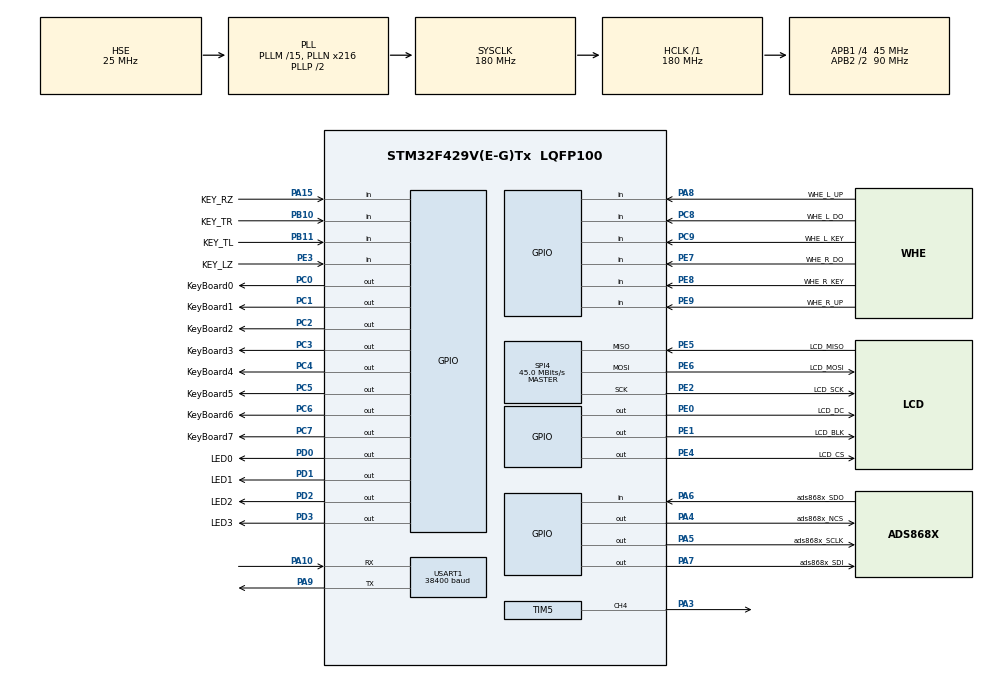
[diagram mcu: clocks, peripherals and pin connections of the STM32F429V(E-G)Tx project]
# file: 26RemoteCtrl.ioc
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DMA2D.ColorMode=DMA2D_OUTPUT_RGB565
Dma.Request0=USART1_TX
Dma.Request1=USART1_RX
Dma.Request2=SPI4_TX
Dma.SPI4_TX.2.Direction=DMA_MEMORY_TO_PERIPH
Dma.SPI4_TX.2.FIFOMode=DMA_FIFOMODE_DISABLE
Dma.SPI4_TX.2.Instance=DMA2_Stream1
Dma.SPI4_TX.2.MemDataAlignment=DMA_MDATAALIGN_HALFWORD
Dma.SPI4_TX.2.MemInc=DMA_MINC_ENABLE
Dma.SPI4_TX.2.Mode=DMA_NORMAL
Dma.SPI4_TX.2.PeriphDataAlignment=DMA_PDATAALIGN_HALFWORD
Dma.SPI4_TX.2.PeriphInc=DMA_PINC_DISABLE
Dma.SPI4_TX.2.Priority=DMA_PRIORITY_LOW
Dma.USART1_RX.1.Direction=DMA_PERIPH_TO_MEMORY
Dma.USART1_RX.1.FIFOMode=DMA_FIFOMODE_DISABLE
Dma.USART1_RX.1.Instance=DMA2_Stream2
Dma.USART1_RX.1.MemDataAlignment=DMA_MDATAALIGN_BYTE
Dma.USART1_RX.1.MemInc=DMA_MINC_ENABLE
Dma.USART1_RX.1.Mode=DMA_NORMAL
Dma.USART1_RX.1.PeriphDataAlignment=DMA_PDATAALIGN_BYTE
Dma.USART1_RX.1.PeriphInc=DMA_PINC_DISABLE
Dma.USART1_RX.1.Priority=DMA_PRIORITY_LOW
Dma.USART1_TX.0.Direction=DMA_MEMORY_TO_PERIPH
Dma.USART1_TX.0.FIFOMode=DMA_FIFOMODE_DISABLE
Dma.USART1_TX.0.Instance=DMA2_Stream7
Dma.USART1_TX.0.MemDataAlignment=DMA_MDATAALIGN_BYTE
Dma.USART1_TX.0.MemInc=DMA_MINC_ENABLE
Dma.USART1_TX.0.Mode=DMA_NORMAL
Dma.USART1_TX.0.PeriphDataAlignment=DMA_PDATAALIGN_BYTE
Dma.USART1_TX.0.PeriphInc=DMA_PINC_DISABLE
Dma.USART1_TX.0.Priority=DMA_PRIORITY_LOW
IWDG.Prescaler=IWDG_PRESCALER_64
IWDG.Reload=500
Mcu.Family=STM32F4
Mcu.Name=STM32F429V(E-G)Tx
Mcu.Package=LQFP100
NVIC.DMA2D_IRQn=true\:5\:0\:true\:false\:true\:true\:true\:true
NVIC.DMA2_Stream1_IRQn=true\:5\:0\:true\:false\:true\:false\:true\:true
NVIC.DMA2_Stream2_IRQn=true\:5\:0\:true\:false\:true\:false\:true\:true
NVIC.DMA2_Stream7_IRQn=true\:5\:0\:true\:false\:true\:false\:true\:true
NVIC.PriorityGroup=NVIC_PRIORITYGROUP_4
NVIC.TIM2_IRQn=true\:5\:0\:true\:false\:true\:true\:true\:true
NVIC.USART1_IRQn=true\:5\:0\:true\:false\:true\:true\:true\:true
PA10.GPIO_PuPd=GPIO_PULLUP
PA10.Mode=Asynchronous
PA10.Signal=USART1_RX
PA13.Mode=Trace_Asynchronous_SW
PA13.Signal=SYS_JTMS-SWDIO
PA14.Mode=Trace_Asynchronous_SW
PA14.Signal=SYS_JTCK-SWCLK
PA15.GPIO_Label=KEY_RZ
PA15.GPIO_PuPd=GPIO_PULLUP
PA15.Signal=GPIO_Input
PA3.Signal=S_TIM5_CH4
PA4.GPIO_Label=ads868x_NCS
PA4.GPIO_Speed=GPIO_SPEED_FREQ_VERY_HIGH
PA4.Signal=GPIO_Output
PA5.GPIO_Label=ads868x_SCLK
PA5.GPIO_Speed=GPIO_SPEED_FREQ_VERY_HIGH
PA5.Signal=GPIO_Output
PA6.GPIO_Label=ads868x_SDO
PA6.Signal=GPIO_Input
PA7.GPIO_Label=ads868x_SDI
PA7.GPIO_Speed=GPIO_SPEED_FREQ_VERY_HIGH
PA7.Signal=GPIO_Output
PA8.GPIO_Label=WHE_L_UP
PA8.GPIO_PuPd=GPIO_PULLDOWN
PA8.Signal=GPIO_Input
PA9.GPIO_PuPd=GPIO_PULLUP
PA9.Mode=Asynchronous
PA9.Signal=USART1_TX
PB10.GPIO_Label=KEY_TR
PB10.GPIO_PuPd=GPIO_PULLUP
PB10.Signal=GPIO_Input
PB11.GPIO_Label=KEY_TL
PB11.GPIO_PuPd=GPIO_PULLUP
PB11.Signal=GPIO_Input
PB3.Mode=Trace_Asynchronous_SW
PB3.Signal=SYS_JTDO-SWO
PC0.GPIO_Label=KeyBoard0
PC0.GPIO_ModeDefaultOutputPP=GPIO_MODE_OUTPUT_OD
PC0.GPIO_PuPd=GPIO_PULLUP
PC0.GPIO_Speed=GPIO_SPEED_FREQ_HIGH
PC0.Signal=GPIO_Output
PC1.GPIO_Label=KeyBoard1
PC1.GPIO_ModeDefaultOutputPP=GPIO_MODE_OUTPUT_OD
PC1.GPIO_PuPd=GPIO_PULLUP
PC1.GPIO_Speed=GPIO_SPEED_FREQ_HIGH
PC1.Signal=GPIO_Output
PC14/OSC32_IN.Mode=LSE-External-Oscillator
PC14/OSC32_IN.Signal=RCC_OSC32_IN
PC15/OSC32_OUT.Mode=LSE-External-Oscillator
PC15/OSC32_OUT.Signal=RCC_OSC32_OUT
PC2.GPIO_Label=KeyBoard2
PC2.GPIO_ModeDefaultOutputPP=GPIO_MODE_OUTPUT_OD
PC2.GPIO_PuPd=GPIO_PULLUP
PC2.GPIO_Speed=GPIO_SPEED_FREQ_HIGH
PC2.Signal=GPIO_Output
PC3.GPIO_Label=KeyBoard3
PC3.GPIO_ModeDefaultOutputPP=GPIO_MODE_OUTPUT_OD
PC3.GPIO_PuPd=GPIO_PULLUP
PC3.GPIO_Speed=GPIO_SPEED_FREQ_HIGH
PC3.Signal=GPIO_Output
PC4.GPIO_Label=KeyBoard4
PC4.GPIO_ModeDefaultOutputPP=GPIO_MODE_OUTPUT_OD
PC4.GPIO_PuPd=GPIO_PULLUP
PC4.GPIO_Speed=GPIO_SPEED_FREQ_HIGH
PC4.Signal=GPIO_Output
PC5.GPIO_Label=KeyBoard5
PC5.GPIO_ModeDefaultOutputPP=GPIO_MODE_OUTPUT_OD
PC5.GPIO_PuPd=GPIO_PULLUP
PC5.GPIO_Speed=GPIO_SPEED_FREQ_HIGH
PC5.Signal=GPIO_Output
PC6.GPIO_Label=KeyBoard6
PC6.GPIO_ModeDefaultOutputPP=GPIO_MODE_OUTPUT_OD
PC6.GPIO_PuPd=GPIO_PULLUP
PC6.GPIO_Speed=GPIO_SPEED_FREQ_HIGH
PC6.Signal=GPIO_Output
PC7.GPIO_Label=KeyBoard7
PC7.GPIO_ModeDefaultOutputPP=GPIO_MODE_OUTPUT_OD
PC7.GPIO_PuPd=GPIO_PULLUP
PC7.GPIO_Speed=GPIO_SPEED_FREQ_HIGH
PC7.Signal=GPIO_Output
PC8.GPIO_Label=WHE_L_DO
PC8.GPIO_PuPd=GPIO_PULLDOWN
PC8.Signal=GPIO_Input
PC9.GPIO_Label=WHE_L_KEY
PC9.GPIO_PuPd=GPIO_PULLDOWN
PC9.Signal=GPIO_Input
PD0.GPIO_Label=LED0
PD0.GPIO_PuPd=GPIO_PULLUP
PD0.PinState=GPIO_PIN_SET
PD0.Signal=GPIO_Output
PD1.GPIO_Label=LED1
PD1.GPIO_PuPd=GPIO_PULLUP
PD1.PinState=GPIO_PIN_SET
PD1.Signal=GPIO_Output
PD2.GPIO_Label=LED2
PD2.GPIO_ModeDefaultOutputPP=GPIO_MODE_OUTPUT_PP
PD2.GPIO_PuPd=GPIO_PULLUP
PD2.PinState=GPIO_PIN_SET
PD2.Signal=GPIO_Output
PD3.GPIO_Label=LED3
PD3.GPIO_PuPd=GPIO_PULLUP
PD3.PinState=GPIO_PIN_SET
PD3.Signal=GPIO_Output
PE0.GPIO_Label=LCD_DC
PE0.GPIO_Speed=GPIO_SPEED_FREQ_VERY_HIGH
PE0.Signal=GPIO_Output
PE1.GPIO_Label=LCD_BLK
PE1.GPIO_Speed=GPIO_SPEED_FREQ_VERY_HIGH
PE1.PinState=GPIO_PIN_SET
PE1.Signal=GPIO_Output
PE2.GPIO_Label=LCD_SCK
PE2.Mode=Full_Duplex_Master
PE2.Signal=SPI4_SCK
PE3.GPIO_Label=KEY_LZ
PE3.GPIO_PuPd=GPIO_PULLUP
PE3.Signal=GPIO_Input
PE4.GPIO_Label=LCD_CS
PE4.GPIO_Speed=GPIO_SPEED_FREQ_HIGH
PE4.Signal=GPIO_Output
PE5.GPIO_Label=LCD_MISO
PE5.Mode=Full_Duplex_Master
PE5.Signal=SPI4_MISO
PE6.GPIO_Label=LCD_MOSI
PE6.Mode=Full_Duplex_Master
PE6.Signal=SPI4_MOSI
PE7.GPIO_Label=WHE_R_DO
PE7.GPIO_PuPd=GPIO_PULLDOWN
PE7.Signal=GPIO_Input
PE8.GPIO_Label=WHE_R_KEY
PE8.GPIO_PuPd=GPIO_PULLDOWN
PE8.Signal=GPIO_Input
PE9.GPIO_Label=WHE_R_UP
PE9.GPIO_PuPd=GPIO_PULLDOWN
PE9.Signal=GPIO_Input
PH0/OSC_IN.Mode=HSE-External-Oscillator
PH0/OSC_IN.Signal=RCC_OSC_IN
PH1/OSC_OUT.Mode=HSE-External-Oscillator
PH1/OSC_OUT.Signal=RCC_OSC_OUT
ProjectManager.HeapSize=0x200
ProjectManager.StackSize=0x400
ProjectManager.TargetToolchain=MDK-ARM V5.32
RCC.48MHZClocksFreq_Value=90000000
RCC.AHBFreq_Value=180000000
RCC.APB1CLKDivider=RCC_HCLK_DIV4
RCC.APB1Freq_Value=45000000
RCC.APB1TimFreq_Value=90000000
RCC.APB2CLKDivider=RCC_HCLK_DIV2
RCC.APB2Freq_Value=90000000
RCC.APB2TimFreq_Value=180000000
RCC.CortexFreq_Value=180000000
RCC.HCLKFreq_Value=180000000
RCC.HSE_VALUE=25000000
RCC.HSI_VALUE=16000000
RCC.PLLM=15
RCC.PLLN=216
RCC.PLLSourceVirtual=RCC_PLLSOURCE_HSE
RCC.SYSCLKFreq_VALUE=180000000
RCC.SYSCLKSource=RCC_SYSCLKSOURCE_PLLCLK
RCC.VCOOutputFreq_Value=360000000
SH.S_TIM5_CH4.0=TIM5_CH4,PWM Generation4 CH4
SPI4.BaudRatePrescaler=SPI_BAUDRATEPRESCALER_2
SPI4.CalculateBaudRate=45.0 MBits/s
SPI4.Direction=SPI_DIRECTION_2LINES
SPI4.Mode=SPI_MODE_MASTER
SPI4.VirtualType=VM_MASTER
STMicroelectronics.X-CUBE-TOUCHGFX.4.26.1.ApplicationCcGraphicsJjApplication=TouchGFXOoGenerator
STMicroelectronics.X-CUBE-TOUCHGFX.4.26.1.tgfx_block_size=10240
STMicroelectronics.X-CUBE-TOUCHGFX.4.26.1.tgfx_buffering_strategy=Partial
STMicroelectronics.X-CUBE-TOUCHGFX.4.26.1.tgfx_custom_height=320
STMicroelectronics.X-CUBE-TOUCHGFX.4.26.1.tgfx_custom_width=240
STMicroelectronics.X-CUBE-TOUCHGFX.4.26.1.tgfx_hardware_accelerator=dma_2d
STMicroelectronics.X-CUBE-TOUCHGFX.4.26.1.tgfx_number_of_blocks=6
STMicroelectronics.X-CUBE-TOUCHGFX.4.26.1.tgfx_oswrapper=Custom
STMicroelectronics.X-CUBE-TOUCHGFX.4.26.1_IsPackSelfContextualization=true
TIM2.Period=333
TIM2.Prescaler=8999
TIM5.AutoReloadPreload=TIM_AUTORELOAD_PRELOAD_ENABLE
TIM5.Channel-PWM\ Generation4\ CH4=TIM_CHANNEL_4
TIM5.Period=65535
TIM5.Prescaler=90-1
USART1.BaudRate=38400
USART1.VirtualMode=VM_ASYNC
VP_CRC_VS_CRC.Mode=CRC_Activate
VP_DMA2D_VS_DMA2D.Mode=DMA2D_Activate
VP_IWDG_VS_IWDG.Mode=IWDG_Activate
VP_STMicroelectronics.X-CUBE-TOUCHGFX_VS_GraphicsJjApplication_4.26.1.Mode=GraphicsJjApplication
VP_TIM2_VS_ClockSourceINT.Mode=Internal
VP_TIM5_VS_ClockSourceINT.Mode=Internal
board=custom

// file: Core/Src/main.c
/* USER CODE BEGIN Header */
/**
  ******************************************************************************
  * @file           : main.c
  * @brief          : Main program body
  ******************************************************************************
  * @attention
  *
  * Copyright (c) 2026 STMicroelectronics.
  * All rights reserved.
  *
  * This software is licensed under terms that can be found in the LICENSE file
  * in the root directory of this software component.
  * If no LICENSE file comes with this software, it is provided AS-IS.
  *
  ******************************************************************************
  */
/* USER CODE END Header */
#include "main.h"
#include "crc.h"
#include "dma.h"
#include "dma2d.h"
#include "iwdg.h"
#include "spi.h"
#include "tim.h"
#include "usart.h"
#include "gpio.h"
#include "app_touchgfx.h"

/* USER CODE BEGIN Includes */
#include <bsp.h>
/* USER CODE END Includes */

void SystemClock_Config(void);
/* USER CODE BEGIN PFP */
extern void freertos_start(void);
/* USER CODE END PFP */

int main(void)
{

  /* MCU Configuration--------------------------------------------------------*/

  /* Reset of all peripherals, Initializes the Flash interface and the Systick. */
  HAL_Init();

  /* USER CODE BEGIN Init */
  delay_init(180);
  /* USER CODE END Init */

  /* Configure the system clock */
  SystemClock_Config();

  /* Initialize all configured peripherals */
  MX_GPIO_Init();
  MX_DMA_Init();
  MX_USART1_UART_Init();
  MX_CRC_Init();
  MX_DMA2D_Init();
  MX_SPI4_Init();
  MX_TIM2_Init();
  MX_IWDG_Init();
  MX_TIM5_Init();
  MX_TouchGFX_Init();
  /* USER CODE BEGIN 2 */

  bsp_init();

  freertos_start();
  /* USER CODE END 2 */

  /* Infinite loop */
  /* USER CODE BEGIN WHILE */
#if 0
  while (1)
  {
    /* USER CODE END WHILE */

  MX_TouchGFX_Process();
    /* USER CODE BEGIN 3 */
  }
#endif /* 0 */
  /* USER CODE END 3 */
}

void SystemClock_Config(void)
{
  RCC_OscInitTypeDef RCC_OscInitStruct = {0};
  RCC_ClkInitTypeDef RCC_ClkInitStruct = {0};

  /** Configure the main internal regulator output voltage
  */
  __HAL_RCC_PWR_CLK_ENABLE();
  __HAL_PWR_VOLTAGESCALING_CONFIG(PWR_REGULATOR_VOLTAGE_SCALE1);

  /** Initializes the RCC Oscillators according to the specified parameters
  * in the RCC_OscInitTypeDef structure.
  */
  RCC_OscInitStruct.OscillatorType = RCC_OSCILLATORTYPE_LSI|RCC_OSCILLATORTYPE_HSE;
  RCC_OscInitStruct.HSEState = RCC_HSE_ON;
  RCC_OscInitStruct.LSIState = RCC_LSI_ON;
  RCC_OscInitStruct.PLL.PLLState = RCC_PLL_ON;
  RCC_OscInitStruct.PLL.PLLSource = RCC_PLLSOURCE_HSE;
  RCC_OscInitStruct.PLL.PLLM = 15;
  RCC_OscInitStruct.PLL.PLLN = 216;
  RCC_OscInitStruct.PLL.PLLP = RCC_PLLP_DIV2;
  RCC_OscInitStruct.PLL.PLLQ = 4;
  if (HAL_RCC_OscConfig(&RCC_OscInitStruct) != HAL_OK)
  {
    Error_Handler();
  }

  /** Activate the Over-Drive mode
  */
  if (HAL_PWREx_EnableOverDrive() != HAL_OK)
  {
    Error_Handler();
  }

  /** Initializes the CPU, AHB and APB buses clocks
  */
  RCC_ClkInitStruct.ClockType = RCC_CLOCKTYPE_HCLK|RCC_CLOCKTYPE_SYSCLK
                              |RCC_CLOCKTYPE_PCLK1|RCC_CLOCKTYPE_PCLK2;
  RCC_ClkInitStruct.SYSCLKSource = RCC_SYSCLKSOURCE_PLLCLK;
  RCC_ClkInitStruct.AHBCLKDivider = RCC_SYSCLK_DIV1;
  RCC_ClkInitStruct.APB1CLKDivider = RCC_HCLK_DIV4;
  RCC_ClkInitStruct.APB2CLKDivider = RCC_HCLK_DIV2;

  if (HAL_RCC_ClockConfig(&RCC_ClkInitStruct, FLASH_LATENCY_5) != HAL_OK)
  {
    Error_Handler();
  }
}

void Error_Handler(void)
{
    __disable_irq();
    while (1) {}
}
